# STM32L1xx register map
File version: 1.1
CPU: 
Registers are 32-bit, read-write, reset 0x0 unless marked. A register's access mark holds for its fields unless they carry their own. Offsets are from the block's base; [hi:lo] are bit positions; {n}, {i} and the like mark numbered series.

## AES — Advanced encrytion standard hardware accelerator
Base 0x50060000
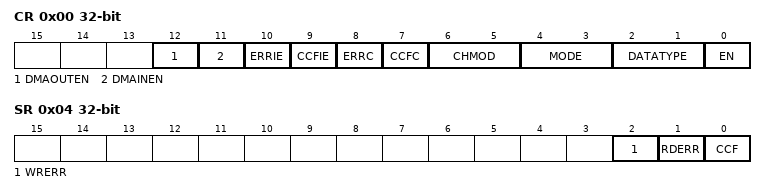
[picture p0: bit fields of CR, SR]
0x00 CR — control register
  [12] DMAOUTEN — Enable DMA management of data output phase
  [11] DMAINEN — Enable DMA management of data input phase
  [10] ERRIE — Error interrupt enable
  [9] CCFIE — CCF flag interrupt enable
  [8] ERRC — Error clear
  [7] CCFC — Computation Complete Flag Clear
  [6:5] CHMOD — AES chaining mode
  [4:3] MODE — AES operating mode
  [2:1] DATATYPE — Data type selection
  [0] EN — AES enable
0x04 SR ro — Status register
  [2] WRERR — Write error flag
  [1] RDERR — Read error flag
  [0] CCF — Computation complete flag
0x08 DINR — Data input register
  [31:0] DINR — Data input
0x0C DOUTR ro — Data output register
  [31:0] DOUTR — Data output
{0x10+4i} KEYR{i} (i=0..3) — AES Key register {i}
  [31:0] KEYR{i} — AES key
{0x20+4i} IVR{i} (i=0..3) — Initialization Vector Register {i}
  [31:0] IVR{i} — Initialization Vector Register

## C_ADC — Common ADC registers
Base 0x40012700
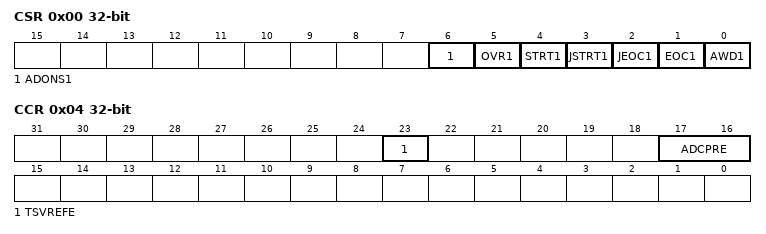
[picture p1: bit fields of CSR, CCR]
0x00 CSR ro — ADC Common status register
  [6] ADONS1 — ADON Status of ADC
  [5] OVR1 — Overrun flag of ADC 1
  [4] STRT1 — Regular channel Start flag of ADC 1
  [3] JSTRT1 — Injected channel Start flag of ADC 1
  [2] JEOC1 — Injected channel end of conversion of ADC 1
  [1] EOC1 — End of conversion of ADC 1
  [0] AWD1 — Analog watchdog flag of ADC 1
0x04 CCR — ADC common control register
  [23] TSVREFE — Temperature sensor and VREFINT enable
  [17:16] ADCPRE — ADC prescaler

## COMP — Comparators
Base 0x40007C00
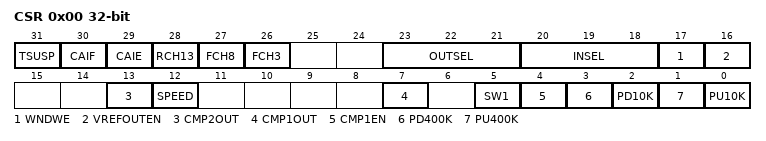
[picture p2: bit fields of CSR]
0x00 CSR access per field — comparator control and status register
  [31] TSUSP rw — Suspend Timer Mode
  [30] CAIF ro — Channel acquisition interrupt flag
  [29] CAIE rw — Channel Acquisition Interrupt Enable / Clear
  [28] RCH13 rw — Select GPIO port PC3 as re-routed ADC input channel CH13.
  [27] FCH8 rw — Select GPIO port PB0 as fast ADC input channel CH8.
  [26] FCH3 rw — Select GPIO port PA3 as fast ADC input channel CH3.
  [23:21] OUTSEL rw — Comparator 2 output selection
  [20:18] INSEL rw — Inverted input selection
  [17] WNDWE rw — Window mode enable
  [16] VREFOUTEN rw — VREFINT output enable
  [13] CMP2OUT ro — Comparator 2 output
  [12] SPEED rw — Comparator 2 speed mode
  [7] CMP1OUT ro — Comparator 1 output
  [5] SW1 rw — SW1 analog switch enable
  [4] CMP1EN rw — Comparator 1 enable
  [3] PD400K rw — 400 kO pull-down resistor
  [2] PD10K rw — 10 kO pull-down resistor
  [1] PU400K rw — 400 kO pull-up resistor
  [0] PU10K rw — 10 kO pull-up resistor

## CRC — CRC calculation unit
Base 0x40023000
0x00 DR reset 0xFFFFFFFF — Data register
  [31:0] Data_register
0x04 IDR — Independent data register
  [6:0] Independent_data_register
0x08 CR wo — Control register
  [0] RESET

## DAC — Digital-to-analog converter
Base 0x40007400
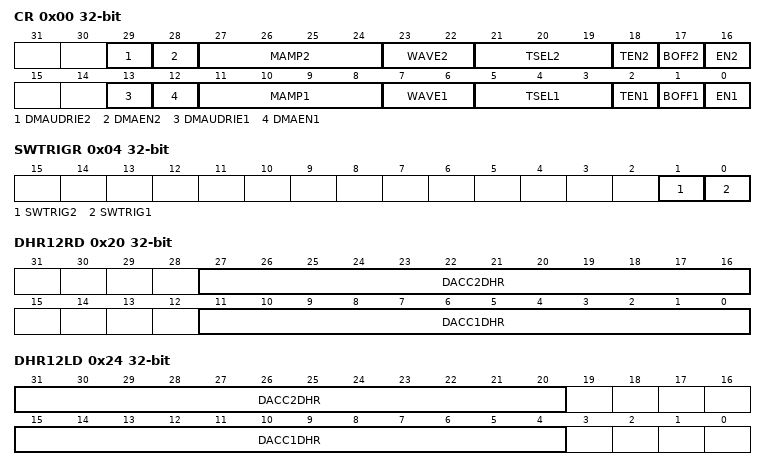
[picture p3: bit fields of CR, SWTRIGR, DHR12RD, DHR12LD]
0x00 CR — control register
  [29] DMAUDRIE2 — DAC channel2 DMA underrun interrupt enable
  [28] DMAEN2 — DAC channel2 DMA enable
  [27:24] MAMP2 — DAC channel2 mask/amplitude selector
  [23:22] WAVE2 — DAC channel2 noise/triangle wave generation enable
  [21:19] TSEL2 — DAC channel2 trigger selection
  [18] TEN2 — DAC channel2 trigger enable
  [17] BOFF2 — DAC channel2 output buffer disable
  [16] EN2 — DAC channel2 enable
  [13] DMAUDRIE1 — DAC channel1 DMA Underrun Interrupt enable
  [12] DMAEN1 — DAC channel1 DMA enable
  [11:8] MAMP1 — DAC channel1 mask/amplitude selector
  [7:6] WAVE1 — DAC channel1 noise/triangle wave generation enable
  [5:3] TSEL1 — DAC channel1 trigger selection
  [2] TEN1 — DAC channel1 trigger enable
  [1] BOFF1 — DAC channel1 output buffer disable
  [0] EN1 — DAC channel1 enable
0x04 SWTRIGR wo — software trigger register
  [1] SWTRIG2 — DAC channel2 software trigger
  [0] SWTRIG1 — DAC channel1 software trigger
0x08 DHR12R1 — channel1 12-bit right-aligned data holding register
  [11:0] DACC1DHR — DAC channel1 12-bit right-aligned data
0x0C DHR12L1 — channel1 12-bit left aligned data holding register
  [15:4] DACC1DHR — DAC channel1 12-bit left-aligned data
0x10 DHR8R1 — channel1 8-bit right aligned data holding register
  [7:0] DACC1DHR — DAC channel1 8-bit right-aligned data
0x14 DHR12R2 — channel2 12-bit right aligned data holding register
  [11:0] DACC2DHR — DAC channel2 12-bit right-aligned data
0x18 DHR12L2 — channel2 12-bit left aligned data holding register
  [15:4] DACC2DHR — DAC channel2 12-bit left-aligned data
0x1C DHR8R2 — channel2 8-bit right-aligned data holding register
  [7:0] DACC2DHR — DAC channel2 8-bit right-aligned data
0x20 DHR12RD — Dual DAC 12-bit right-aligned data holding register
  [27:16] DACC2DHR — DAC channel2 12-bit right-aligned data
  [11:0] DACC1DHR — DAC channel1 12-bit right-aligned data
0x24 DHR12LD — DUAL DAC 12-bit left aligned data holding register
  [31:20] DACC2DHR — DAC channel2 12-bit left-aligned data
  [15:4] DACC1DHR — DAC channel1 12-bit left-aligned data
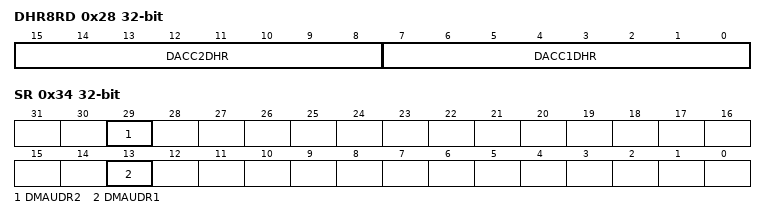
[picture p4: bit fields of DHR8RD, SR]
0x28 DHR8RD — DUAL DAC 8-bit right aligned data holding register
  [15:8] DACC2DHR — DAC channel2 8-bit right-aligned data
  [7:0] DACC1DHR — DAC channel1 8-bit right-aligned data
0x2C DOR1 ro — channel1 data output register
  [11:0] DACC1DOR — DAC channel1 data output
0x30 DOR2 ro — channel2 data output register
  [11:0] DACC2DOR — DAC channel2 data output
0x34 SR — status register
  [29] DMAUDR2 — DAC channel2 DMA underrun flag
  [13] DMAUDR1 — DAC channel1 DMA underrun flag
